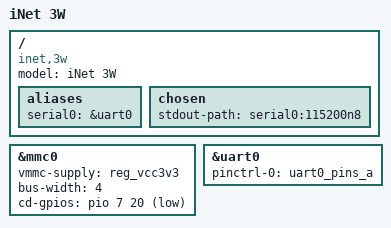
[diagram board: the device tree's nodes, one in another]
// SPDX-License-Identifier: GPL-2.0+ OR X11
/*
 * Copyright 2015 Hans de Goede <hdegoede@redhat.com>
 *
 * Minimal dts file for the iNet 3W for u-boot only
 */

/dts-v1/;
#include "sun4i-a10.dtsi"
#include "sunxi-common-regulators.dtsi"
#include <dt-bindings/gpio/gpio.h>

/ {
	model = "iNet 3W";
	compatible = "inet,3w", "allwinner,sun4i-a10";

	aliases {
		serial0 = &uart0;
	};

	chosen {
		stdout-path = "serial0:115200n8";
	};
};

&mmc0 {
	vmmc-supply = <&reg_vcc3v3>;
	bus-width = <4>;
	cd-gpios = <&pio 7 20 GPIO_ACTIVE_LOW>; /* PH20 */
	status = "okay";
};

&uart0 {
	pinctrl-names = "default";
	pinctrl-0 = <&uart0_pins_a>;
	status = "okay";
};
